# APM32F445 register map
File version: 1.0
CPU: CM4 r0p1, little endian, MPU, FPU, 4 interrupt priority bits
Registers are 32-bit, read-write, reset 0x0 unless marked. A register's access mark holds for its fields unless they carry their own. Offsets are from the block's base; [hi:lo] are bit positions; {n}, {i} and the like mark numbered series; 'fields as' and 'values as' point back to an identical list.

## DMA — Direct Memory Access
Base 0x40008000
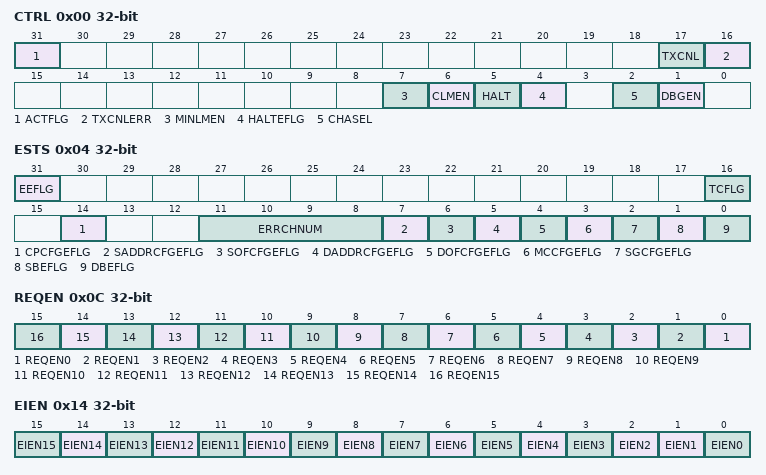
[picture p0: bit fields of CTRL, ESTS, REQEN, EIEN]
0x00 CTRL — Control Register
  [31] ACTFLG ro — DMA Active Flag
    0=eDMA is idle; 1=eDMA is executing a channel
  [17] TXCNL — Data Transfer Cancel
    0=Normal operation; 1=Cancel the remaining data transfer. Stop the executing channel and force the minor loop to finish. The cancel takes effect after the last write of the current read/write sequence. The TXCNL bit clears itself after the cancel has been honored. This cancel retires the channel normally as if the minor loop was completed.
  [16] TXCNLERR — Data Transfer Cancel Error
    0=Normal operation; 1=Cancel the remaining data transfer in the same fashion as the TXCNL bit. Stop the executing channel and force the minor loop to finish. The cancel takes effect after the last write of the current read/write sequence. The TXCNLERR bit clears itself after the cancel is honored. In addition to cancelling the transfer, TXCNLERR treats the cancel as an error condition, thus updating the Error Status register (DMAx_ES) and generating an optional error interrupt.
  [7] MINLMEN — Minor Loop Mapping Enable
    0=Disabled. TCDn.word2 is defined as a 32-bit NBYTES field.; 1=Enabled. TCDn.word2 is redefined to include individual enable fields, an offset field, and the MINBTCNT field. The individual enable fields allow the minor loop offset to be applied to the source address, the destination address, or both. The MINBTCNT field is reduced when either offset is enabled.
  [6] CLMEN — Continuous Link Mode Enable
    0=A minor loop channel link made to itself goes through channel arbitration before being activated again; 1=A minor loop channel link made to itself does not go through channel arbitration before being activated again. Upon minor loop completion, the channel activates again if that channel has a minor loop channel link enabled and the link channel is itself. This effectively applies the minor loop offsets and restarts the next minor loop.
  [5] HALT — DMA Operations Halt
    0=Normal operation; 1=Stall the start of any new channels. Executing channels are allowed to complete. Channel execution resumes when this bit is cleared.
  [4] HALTEFLG — HALT Error Flag
    0=Normal operation; 1=Any error causes the HALT bit to set. Subsequently, all service requests are ignored until the HALT bit is cleared.
  [2] CHASEL — Channel Arbitration Mode Select
  [1] DBGEN — Debug Enable
0x04 ESTS ro — Error Status Register
  [31] EEFLG — Error Exist Flag
    0=No ERR bits are set; 1=At least one ERR bit is set indicating a valid error exists that has not been cleared
  [16] TCFLG — Transfer Canceled Flag
    0=No canceled transfers; 1=The last recorded entry was a canceled transfer by the error cancel transfer input
  [14] CPCFGEFLG — Channel Priority Configure Error Flag
    0=No channel priority error
  [11:8] ERRCHNUM — Error Channel Number
  [7] SADDRCFGEFLG — Source Address Configure Error Flag
    0=No source address configuration error; 1=The last recorded error was a configuration error detected in the TCDn_SADDR field. TCDn_SADDR is inconsistent with TCDn_TATT[SSIZE].
  [6] SOFCFGEFLG — Source Offset Configure Error Flag
    0=No source offset configuration error; 1=The last recorded error was a configuration error detected in the TCDn_SADDROF field. TCDn_SADDROF is inconsistent with TCDn_TATT[SSIZE].
  [5] DADDRCFGEFLG — Destination Address Configure Error Flag
    0=No destination address configuration error; 1=The last recorded error was a configuration error detected in the TCDn_DADDR field. TCDn_DADDR is inconsistent with TCDn_TATT[DSIZE].
  [4] DOFCFGEFLG — Destination Offset Configure Error Flag
    0=No destination offset configuration error; 1=The last recorded error was a configuration error detected in the TCDn_DADDRSOF field. TCDn_DADDRSOF is inconsistent with TCDn_TATT[DSIZE].
  [3] MCCFGEFLG — MINBTCNT/CMAJICNT Configure Error Flag
    0=No NBYTES/CITER configuration error
  [2] SGCFGEFLG — Scatter/Gather Configure Error Flag
    0=No scatter/gather configuration error; 1=The last recorded error was a configuration error detected in the TCDn_DADDRAVSGA field. This field is checked at the beginning of a scatter/gather operation after major loop completion if TCDn_CSTS[SGFEN] is enabled. TCDn_DADDRAVSGA is not on a 32 byte boundary.
  [1] SBEFLG — Source Bus Error Flag
    0=No source bus error; 1=The last recorded error was a bus error on a source read
  [0] DBEFLG — Destination Bus Error Flag
    0=No destination bus error; 1=The last recorded error was a bus error on a destination write
0x0C REQEN — Request Enable Register
  [all] fields
    0=The DMA request signal for the corresponding channel is disabled; 1=The DMA request signal for the corresponding channel is enabled
  [n] REQEN{n} (n=0..15) — Channel {n} DMA Request Enable
0x14 EIEN — Error Interrupt Enable Register
  [all] fields
    0=The error signal for corresponding channel does not generate an error interrupt; 1=The assertion of the error signal for corresponding channel generates an error interrupt request
  [n] EIEN{n} (n=2..15) — Channel {n} Error Interrupt Enable
  [1] EIEN1 — Error Interrupt Channel 1 Enable
  [0] EIEN0 — Error Interrupt Channel 0 Enable
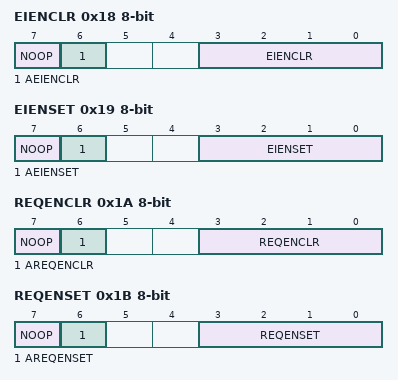
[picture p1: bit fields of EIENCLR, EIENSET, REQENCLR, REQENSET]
0x18 EIENCLR 8-bit wo — Error Interrupt Enable Clear Register
  [7] NOOP — No Operation
    0=Normal operation; 1=No operation, ignore the other bits in this register
  [6] AEIENCLR — All Channel Error Interrupt Bits Clear
  [3:0] EIENCLR — Channel Error Interrupt Enable Bit Clear
0x19 EIENSET 8-bit wo — Error Interrupt Enable Set Register
  [7] NOOP — No Operation
    values as EIENCLR.NOOP
  [6] AEIENSET — All Channel Error Interrupt Bits Set
  [3:0] EIENSET — Channel Error Interrupt Enable Bit Set
0x1A REQENCLR 8-bit wo — Request Enable Clear Register
  [7] NOOP — No Operation
    values as EIENCLR.NOOP
  [6] AREQENCLR — All DMA Requests Enable Clear
  [3:0] REQENCLR — DMA Request Enable Clear
0x1B REQENSET 8-bit wo — Request Enable Set Register
  [7] NOOP — No Operation
    values as EIENCLR.NOOP
  [6] AREQENSET — ALL DMA Requests Enable Set
  [3:0] REQENSET — DMA Request Enable Setup
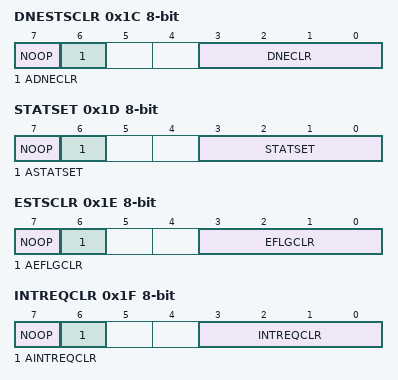
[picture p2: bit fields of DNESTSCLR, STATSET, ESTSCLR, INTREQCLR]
0x1C DNESTSCLR 8-bit wo — DONE Status Clear Register
  [7] NOOP — No Operation
    values as EIENCLR.NOOP
  [6] ADNECLR — All DONE Field Clear
    0=Clears only the TCDn_CSTS[MAJILINKEN] bit specified in the DNECLR field; 1=Clears all bits in TCDn_CSTS[MAJILINKEN]
  [3:0] DNECLR — DONE Field Clear
0x1D STATSET 8-bit wo — START Set Register
  [7] NOOP — No Operation
    values as EIENCLR.NOOP
  [6] ASTATSET — All START Field Setup
    0=Set only the TCDn_CSTS[START] bit specified in the STATSET field; 1=Set all bits in TCDn_CSTS[START]
  [3:0] STATSET — START Field Set
0x1E ESTSCLR 8-bit wo — Error Status Clear Register
  [7] NOOP — No Operation
    values as EIENCLR.NOOP
  [6] AEFLGCLR — All Error Flag Clear
  [3:0] EFLGCLR — Error Flag Clear
0x1F INTREQCLR 8-bit wo — Interrupt Request Clear Register
  [7] NOOP — No Operation
    values as EIENCLR.NOOP
  [6] AINTREQCLR — All Interrupt Request Clear
  [3:0] INTREQCLR — Interrupt Request Clear
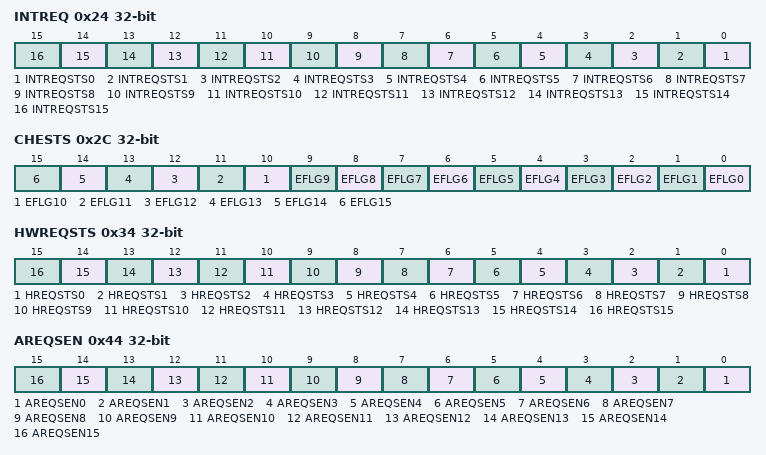
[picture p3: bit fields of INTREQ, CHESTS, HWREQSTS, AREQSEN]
0x24 INTREQ — Interrupt Request Register
  [all] fields
    0=The interrupt request for corresponding channel is cleared; 1=The interrupt request for corresponding channel is active
  [n] INTREQSTS{n} (n=0..15) — Interrupt Request {n} Status
0x2C CHESTS — Channel Error Status Register
  [all] fields
    0=An error in this channel has not occurred; 1=An error in this channel has occurred
  [n] EFLG{n} (n=0..15) — Error In Channel {n} Flag
0x34 HWREQSTS ro — Hardware Request Status Register
  [n] HREQSTS{n} (n=0..15) — Hardware Request Channel {n} Status
    0=A hardware service request for channel {n} is not present; 1=A hardware service request for channel {n} is present
0x44 AREQSEN — Asynchronous Request in Stop Enable Register
  [n] AREQSEN{n} (n=0..15) — Asynchronous DMA Request Channel {n} in Stop Mode Enable
    0=Disable asynchronous DMA request for channel {n}; 1=Enable asynchronous DMA request for channel {n}
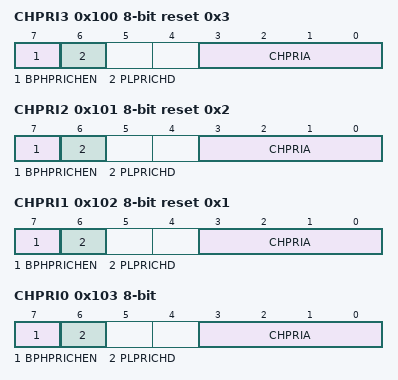
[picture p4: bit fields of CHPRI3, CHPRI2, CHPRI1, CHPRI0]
0x100 CHPRI3 8-bit reset 0x3 — Channel 3 Priority Register
  [7] BPHPRICHEN — being Preempted by Other Higher Channel Enable
    0=Channel n cannot be suspended by a higher priority channel's service request; 1=Channel n can be temporarily suspended by the service request of a higher priority channel
  [6] PLPRICHD — Preemption of Other Lower Priority Channel Disable
    0=Channel n can suspend a lower priority channel; 1=Channel n cannot suspend any channel, regardless of channel priority
  [3:0] CHPRIA — Channel n Priority Arbitration
0x101 CHPRI2 8-bit reset 0x2 — Channel 2 Priority Register
  fields as CHPRI3
0x102 CHPRI1 8-bit reset 0x1 — Channel 1 Priority Register
  fields as CHPRI3
0x103 CHPRI0 8-bit — Channel 0 Priority Register
  fields as CHPRI3
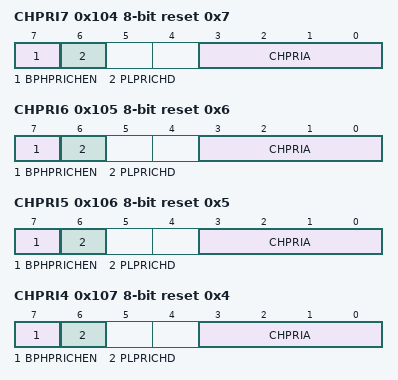
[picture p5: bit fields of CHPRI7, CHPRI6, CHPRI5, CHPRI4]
0x104 CHPRI7 8-bit reset 0x7 — Channel 7 Priority Register
  fields as CHPRI3
0x105 CHPRI6 8-bit reset 0x6 — Channel 6 Priority Register
  fields as CHPRI3
0x106 CHPRI5 8-bit reset 0x5 — Channel 5 Priority Register
  fields as CHPRI3
0x107 CHPRI4 8-bit reset 0x4 — Channel 4 Priority Register
  fields as CHPRI3
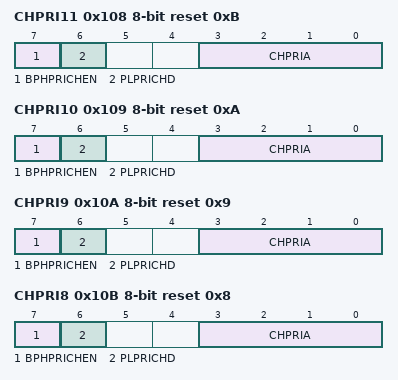
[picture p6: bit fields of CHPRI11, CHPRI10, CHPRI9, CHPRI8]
0x108 CHPRI11 8-bit reset 0xB — Channel 11 Priority Register
  fields as CHPRI3
0x109 CHPRI10 8-bit reset 0xA — Channel 10 Priority Register
  fields as CHPRI3
0x10A CHPRI9 8-bit reset 0x9 — Channel 9 Priority Register
  fields as CHPRI3
0x10B CHPRI8 8-bit reset 0x8 — Channel 8 Priority Register
  fields as CHPRI3
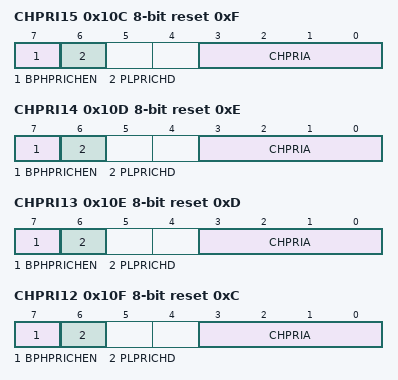
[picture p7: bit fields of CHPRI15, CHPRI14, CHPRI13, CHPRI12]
0x10C CHPRI15 8-bit reset 0xF — Channel 15 Priority Register
  fields as CHPRI3
0x10D CHPRI14 8-bit reset 0xE — Channel 14 Priority Register
  fields as CHPRI3
0x10E CHPRI13 8-bit reset 0xD — Channel 13 Priority Register
  fields as CHPRI3
0x10F CHPRI12 8-bit reset 0xC — Channel 12 Priority Register
  fields as CHPRI3
{0x1000+0x20*i} TCD{i}_SADDR reset not defined (i=0..15) — TCD{i} Source Address
  [31:0] SADDR — Source Data Address
{0x1004+0x20*i} TCD{i}_SADDROF 16-bit reset not defined (i=0..15) — TCD{i} Signed Source Address Offset
  [15:0] SADDROF — Source Address Signed Offset
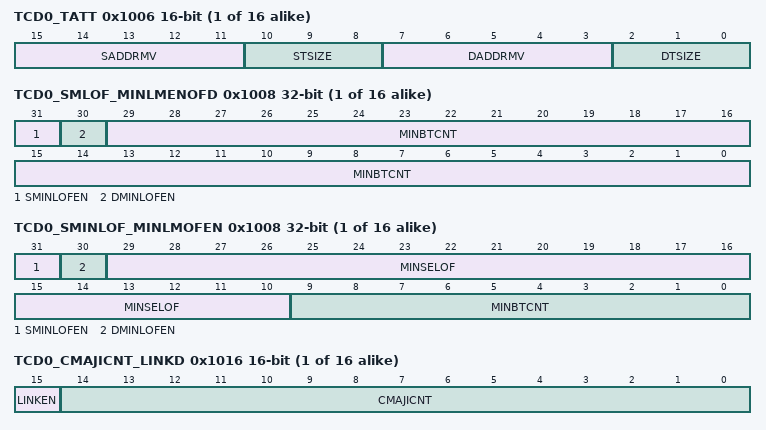
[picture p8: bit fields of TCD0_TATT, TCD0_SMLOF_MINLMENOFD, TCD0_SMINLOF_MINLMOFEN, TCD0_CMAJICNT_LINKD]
{0x1006+0x20*i} TCD{i}_TATT 16-bit reset not defined (i=0..15) — TCD{i} Transfer Attributes
  [15:11] SADDRMV — Source Address Modulo Value
    0=Source address modulo feature is disabled
  [10:8] STSIZE — Source Data Transfer Size
    0=8-bit; 1=16-bit; 2=32-bit
  [7:3] DADDRMV — Destination Address Modulo Value
  [2:0] DTSIZE — Destination Data Transfer Size
{0x1008+0x20*i} TCD{i}_MINBCNT_MINLMD reset not defined (DMA view) (i=0..15) — TCD{i} Minor Byte Transfer Count (Minor Loop Mapping Disabled) Register
  [31:0] MINBTCNT — Minor Byte Number Transfer Count
{0x1008+0x20*i} TCD{i}_SMLOF_MINLMENOFD reset not defined (DMA view) (i=0..15) — TCD{i} Signed Minor Loop Offset (Minor Loop Mapping Enabled and Offset Disabled) Register
  [31] SMINLOFEN — Source Address Minor Loop Offset Enable
    0=The minor loop offset is not applied to the SADDR; 1=The minor loop offset is applied to the SADDR
  [30] DMINLOFEN — Destination Address Minor Loop Offset Enable
    0=The minor loop offset is not applied to the DADDR; 1=The minor loop offset is applied to the DADDR
  [29:0] MINBTCNT — Minor Byte Number Transfer Count
{0x1008+0x20*i} TCD{i}_SMINLOF_MINLMOFEN reset not defined (DMA view) (i=0..15) — TCD{i} Signed Minor Loop Offset (Minor Loop Mapping and Offset Enabled) Register
  [31] SMINLOFEN — Source Address Minor Loop Offset Enable
    values as TCD0_SMLOF_MINLMENOFD.SMINLOFEN
  [30] DMINLOFEN — Destination Address Minor Loop Offset Enable
    values as TCD0_SMLOF_MINLMENOFD.DMINLOFEN
  [29:10] MINSELOF — Minor Loop Sign-extended Offset
  [9:0] MINBTCNT — Minor Byte Number Transfer Count
{0x100C+0x20*i} TCD{i}_SADDRAV reset not defined (i=0..15) — TCD{i} Last Source Address Adjustment
  [31:0] SADDRAV — Source Address Adjustment Value
{0x1010+0x20*i} TCD{i}_DADDR reset not defined (i=0..15) — TCD{i} Destination Address
  [31:0] DADDR — Destination Address
{0x1014+0x20*i} TCD{i}_DADDRSOF 16-bit reset not defined (i=0..15) — TCD{i} Signed Destination Address Offset
  [15:0] DADDRSOF — Destination Address Signed Offset
{0x1016+0x20*i} TCD{i}_CMAJICNT_LINKD 16-bit reset not defined (DMA view) (i=0..15) — TCD{i} Current Major Iteration Count (Channel Linking Disabled) Register
  [15] LINKEN — Channel-to-channel Linking Enable
    0=The channel-to-channel linking is disabled; 1=The channel-to-channel linking is enabled
  [14:0] CMAJICNT — Current Major Iteration Count
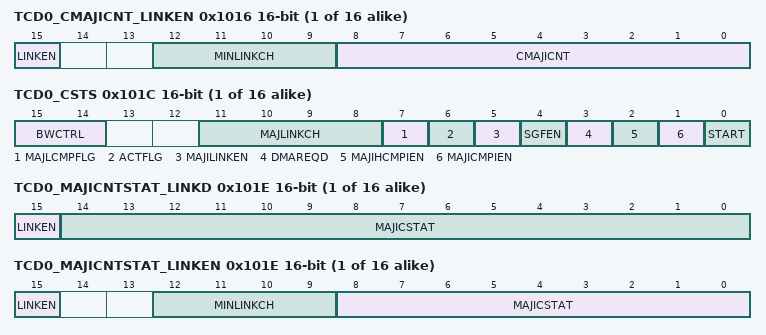
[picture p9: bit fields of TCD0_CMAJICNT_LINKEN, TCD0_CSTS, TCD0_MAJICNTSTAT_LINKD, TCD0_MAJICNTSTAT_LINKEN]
{0x1016+0x20*i} TCD{i}_CMAJICNT_LINKEN 16-bit reset not defined (DMA view) (i=0..15) — TCD{i} Current Major Iteration Count (Channel Linking Enabled) Register
  [15] LINKEN — Channel-to-channel Linking Enable
    values as TCD0_CMAJICNT_LINKD.LINKEN
  [12:9] MINLINKCH — Minor Loop Link Channel Number
  [8:0] CMAJICNT — Current Major Iteration Count
{0x1018+0x20*i} TCD{i}_DADDRAVSGA reset not defined (i=0..15) — TCD{i} Destination Address Adjustment Value or SG next TCD Address Register
  [31:0] DADDRAVSGA — Destination Address Adjustment Value or SG next TCD Address
{0x101C+0x20*i} TCD{i}_CSTS 16-bit reset not defined (i=0..15) — TCD{i} Control and Status Register
  [15:14] BWCTRL — DMA Bandwidth Control
    0=No eDMA engine stalls; 2=eDMA engine stalls for 4 cycles after each R/W; 3=eDMA engine stalls for 8 cycles after each R/W
  [11:8] MAJLINKCH — Major Loop Link Channel Number
  [7] MAJLCMPFLG — Major Loop Complete Flag
  [6] ACTFLG — Channel Active Flag Flag Flag
  [5] MAJILINKEN — Major Iteration Channel-to-channel Linking Enable
    values as TCD0_CMAJICNT_LINKD.LINKEN
  [4] SGFEN — Scatter Gather Format Enable
    0=The current channel's TCD is normal format; 1=The current channel's TCD specifies a scatter gather format. The DADDRAVSGA field provides a memory pointer to the next TCD to be loaded into this channel after the major loop completes its execution.
  [3] DMAREQD — DMA Request Disable
  [2] MAJIHCMPIEN — Major Iteration Counter Half Complete Interrupt Enable
    0=The half-point interrupt is disabled; 1=The half-point interrupt is enabled
  [1] MAJICMPIEN — Major Iteration Count Complete Interrupt Enable
    0=The end-of-major loop interrupt is disabled; 1=The end-of-major loop interrupt is enabled
  [0] START — Channel Start
    0=The channel is not explicitly started; 1=The channel is explicitly started via a software initiated service request
{0x101E+0x20*i} TCD{i}_MAJICNTSTAT_LINKD 16-bit reset not defined (DMA view) (i=0..15) — TCD{i} Major Iteration Count Start(Channel Linking Disabled) Register
  [15] LINKEN — Channel-to-channel Linking Enable
    values as TCD0_CMAJICNT_LINKD.LINKEN
  [14:0] MAJICSTAT — Major Iteration Count Start
{0x101E+0x20*i} TCD{i}_MAJICNTSTAT_LINKEN 16-bit reset not defined (DMA view) (i=0..15) — TCD{i} Major Iteration Count Start (Channel Linking Enabled) Register
  [15] LINKEN — Channel-to-channel Linking Enable
    values as TCD0_CMAJICNT_LINKD.LINKEN
  [12:9] MINLINKCH — Minor Loop Link Channel Number
  [8:0] MAJICSTAT — Major Iteration Count Start
